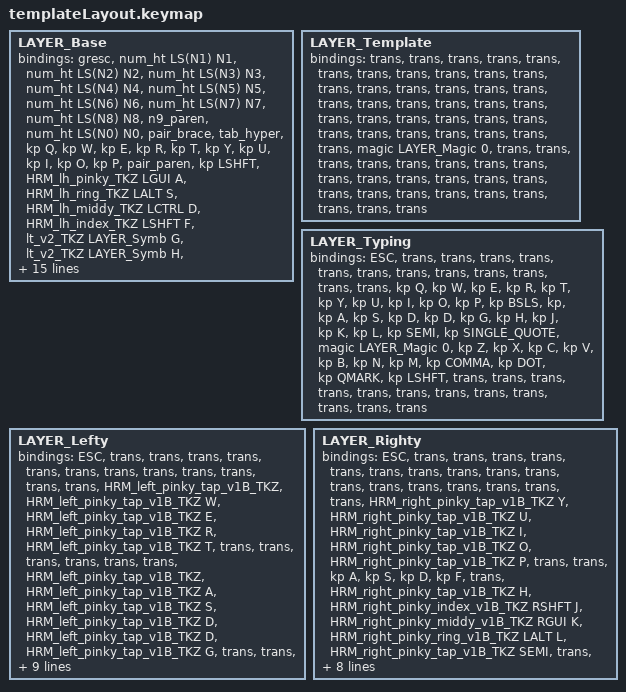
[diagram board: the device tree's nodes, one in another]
/* -------------------------------------------------------------------------- */
/*                    LAYER 0: Base - QWERTY with Home Row Mods               */
/* -------------------------------------------------------------------------- */
#include <behaviors.dtsi>
#include <dt-bindings/zmk/keys.h>
        LAYER_Base {
            bindings = <
/* ╭─────────────────────────────────────╮ ├─────────────────────────────────────┤ ├─────────────────────────────────────┤ ├─────────────────────────────────────┤ ├─────────────────────────────────────┤ ├─────────────────────────────────────┤                                      ├─────────────────────────────────────┤ ├─────────────────────────────────────┤ ├─────────────────────────────────────┤ ├─────────────────────────────────────┤ ├─────────────────────────────────────┤ ├─────────────────────────────────────┤ */
/* │                ESC/`                │ │                   1/!               │ │                   2/@               │ │                 3/#                 │ │                  4/$                │ │                  5/%                │                                      │                  6/^                │ │                   7/&               │ │                  8/*                │ │                   9/()              │ │                 0/)                 │ │                   {}                │ */
                 &gresc                             &num_ht LS(N1) N1                        &num_ht LS(N2) N2                      &num_ht LS(N3) N3                       &num_ht LS(N4) N4                         &num_ht LS(N5) N5                                                            &num_ht LS(N6) N6                      &num_ht LS(N7) N7                         &num_ht LS(N8) N8                           &n9_paren                           &num_ht LS(N0) N0                          &pair_brace
/* ├─────────────────────────────────────┤ ├─────────────────────────────────────┤ ├─────────────────────────────────────┤ ├─────────────────────────────────────┤ ├─────────────────────────────────────┤ ├─────────────────────────────────────┤                                      ├─────────────────────────────────────┤ ├─────────────────────────────────────┤ ├─────────────────────────────────────┤ ├─────────────────────────────────────┤ ├─────────────────────────────────────┤ ├─────────────────────────────────────┤ */
/* │                TAB                  │ │                    Q                │ │                   W                 │ │                   E                 │ │                   R                 │ │                   T                 │                                      │                   Y                 │ │                   U                 │ │                  I                  │ │                  O                  │ │                  P                  │ │                   ()                │ */
                &tab_hyper                                    &kp Q                                  &kp W                                   &kp E                                   &kp R                                 &kp T                                                                           &kp Y                                   &kp U                                   &kp I                                   &kp O                                &kp P                                  &pair_paren
/* ├─────────────────────────────────────┤ ├─────────────────────────────────────┤ ├─────────────────────────────────────┤ ├─────────────────────────────────────┤ ├─────────────────────────────────────┤ ├─────────────────────────────────────┤                                      ├─────────────────────────────────────┤ ├─────────────────────────────────────┤ ├─────────────────────────────────────┤ ├─────────────────────────────────────┤ ├─────────────────────────────────────┤ ├─────────────────────────────────────┤ */
/* │         Lshift + 2xCAPSLCK          │ │            GUI(hold)/A              │ │             ALT(hold)/S             │ │             CTRL(hold)/D            │ │            SHIFT(hold)/F            │ │              SYMB(hold)/G           │                                      │             SYMB(hold)/H            │ │             SHIFT(hold)/J           │ │               CTRL(hold)/K          │ │              ALT(hold)/L            │ │            GUI(hold)/;              │ │                   ""                │ */
                &kp LSHFT                           &HRM_lh_pinky_TKZ LGUI A                &HRM_lh_ring_TKZ LALT S               &HRM_lh_middy_TKZ LCTRL D             &HRM_lh_index_TKZ LSHFT F                   &lt_v2_TKZ LAYER_Symb G                                                     &lt_v2_TKZ LAYER_Symb H                 &HRM_rh_index_TKZ RSHFT J               &HRM_rh_middy_TKZ RCTRL K               &HRM_rh_ring_TKZ RALT L              &HRM_rh_pinky_TKZ RGUI SEMI                        &dqt_pair
/* ├─────────────────────────────────────┤ ├─────────────────────────────────────┤ ├─────────────────────────────────────┤ ├─────────────────────────────────────┤ ├─────────────────────────────────────┤ ├─────────────────────────────────────┤                                      ├─────────────────────────────────────┤ ├─────────────────────────────────────┤ ├─────────────────────────────────────┤ ├─────────────────────────────────────┤ ├─────────────────────────────────────┤ ├─────────────────────────────────────┤ */
/* │               MAGIC                 │ │                    Z                │ │                    X                │ │                  C                  │ │                   V                 │ │                 B                   │                                      │                   N                 │ │                   M                 │ │                 ,/<>                │ │                   .                 │ │                  /                  │ │                 NUMPAD              │ */
          &magic LAYER_Magic 0                                &kp Z                                   &kp X                                 &kp C                                    &kp V                                 &kp B                                                                          &kp N                                  &kp M                                &comma_angle                               &kp DOT                               &kp FSLH                                 &numpad_td
/* ╰─────────────────────────────────────╯ ╰─────────────────────────────────────┤ ├─────────────────────────────────────┤ ├─────────────────────────────────────┤ ├─────────────────────────────────────┤ ╰─────────────────────────────────────╯                                      ╰─────────────────────────────────────╯ ├─────────────────────────────────────┤ ├─────────────────────────────────────┤ ├─────────────────────────────────────┤ ├─────────────────────────────────────┼─┼─────────────────────────────────────╯ */
/*                                                                                 │                  LCTRL              │ │                   LALT              │ │                 CMD                 │                                                                                                                      │            LEFT/WORD-LEFT           │ │                 DOWN                │ │            RIGHT/WORD-RIGHT         │ */
                                                                                                    &kp LCTRL                                &kp LALT                              &kp LGUI                                                                                                                                            &arrow_left LC(LEFT) LEFT                   &upDownArrows                     &arrow_right LC(RIGHT) RIGHT
/*                                                                                 ╰─────────────────────────────────────╯ ╰─────────────────────────────────────╯ ╰─────────────────────────────────────╯                                                                                                                      ╰─────────────────────────────────────╯ ╰─────────────────────────────────────╯ ╰─────────────────────────────────────╯ */
/*                                                                                                                         ├─────────────────────────────────────┤ ├─────────────────────────────────────┤ ├─────────────────────────────────────┤                                      ├─────────────────────────────────────┤ ├─────────────────────────────────────┤ ├─────────────────────────────────────┤ */
/*                                                                                                                         │           NAV(hold)/SPACE           │ │                ENTER                │ │             NUMPAD(hold)/?          │                                      │              SYMB(hold)/.           │ │             BSPC/DEL-WORD           │ │          NAV(hold)/SPACE            │ */
                                                                                                                                &space_v3_TKZ LAYER_Nav SPACE               &lt_v2_TKZ LAYER_Num RET             &lt_v2_TKZ LAYER_Symb QMARK                                                &lt_v2_TKZ LAYER_Symb PERIOD                &bspc_word LA(BSPC) BSPC            &space_v3_TKZ LAYER_Nav SPACE
/*                                                                                                                         ╰─────────────────────────────────────╯ ╰─────────────────────────────────────╯ ╰─────────────────────────────────────╯                                      ╰─────────────────────────────────────╯ ╰─────────────────────────────────────╯ ╰─────────────────────────────────────╯ */
            >;
        };

/* -------------------------------------------------------------------------- */
/*                    LAYER 1: Template                                                */ 
/* -------------------------------------------------------------------------- */
        LAYER_Template {
            bindings = <
/* ╭─────────────────────────────────────╮ ├─────────────────────────────────────┤ ├─────────────────────────────────────┤ ├─────────────────────────────────────┤ ├─────────────────────────────────────┤ ├─────────────────────────────────────┤                                      ├─────────────────────────────────────┤ ├─────────────────────────────────────┤ ├─────────────────────────────────────┤ ├─────────────────────────────────────┤ ├─────────────────────────────────────┤ ├─────────────────────────────────────┤ */
/* │                ---                  │ │                   ---               │ │                  ---                │ │                 ---                 │ │                  ---                │ │                  ---                │                                      │                 ---                 │ │                  ---                │ │                 ---                 │ │                 ---                 │ │                ---                  │ │                  ---                │ */
                 &trans                                     &trans                                  &trans                                  &trans                                  &trans                                 &trans                                                                       &trans                                    &trans                                &trans                                    &trans                                 &trans                                     &trans
/* ├─────────────────────────────────────┤ ├─────────────────────────────────────┤ ├─────────────────────────────────────┤ ├─────────────────────────────────────┤ ├─────────────────────────────────────┤ ├─────────────────────────────────────┤                                      ├─────────────────────────────────────┤ ├─────────────────────────────────────┤ ├─────────────────────────────────────┤ ├─────────────────────────────────────┤ ├─────────────────────────────────────┤ ├─────────────────────────────────────┤ */
/* │                ---                  │ │                   ---               │ │                  ---                │ │                 ---                 │ │                  ---                │ │                 ---                 │                                      │                 ---                 │ │                  ---                │ │                 ---                 │ │                  ---                │ │                ---                  │ │                  ---                │ */
                 &trans                                     &trans                                  &trans                                   &trans                                  &trans                                 &trans                                                                        &trans                                  &trans                                &trans                                  &trans                                 &trans                                     &trans
/* ├─────────────────────────────────────┤ ├─────────────────────────────────────┤ ├─────────────────────────────────────┤ ├─────────────────────────────────────┤ ├─────────────────────────────────────┤ ├─────────────────────────────────────┤                                      ├─────────────────────────────────────┤ ├─────────────────────────────────────┤ ├─────────────────────────────────────┤ ├─────────────────────────────────────┤ ├─────────────────────────────────────┤ ├─────────────────────────────────────┤ */
/* │                ---                  │ │            GUI(hold)/A              │ │                  ---                │ │                 ---                 │ │                  ---                │ │                ---                  │                                      │                 ---                 │ │                  ---                │ │                 ---                 │ │                 ---                 │ │                ---                  │ │                   ---               │ */
                 &trans                                     &trans                                  &trans                                  &trans                                  &trans                                 &trans                                                                        &trans                                   &trans                                &trans                                   &trans                                 &trans                                     &trans
/* ├─────────────────────────────────────┤ ├─────────────────────────────────────┤ ├─────────────────────────────────────┤ ├───────────────────── ───────────────┤ ├─────────────────────────────────────┤ ├─────────────────────────────────────┤                                      ├─────────────────────────────────────┤ ├─────────────────────────────────────┤ ├─────────────────────────────────────┤ ├─────────────────────────────────────┤ ├─────────────────────────────────────┤ ├─────────────────────────────────────┤ */
/* │               MAGIC                 │ │                    Z                │ │                 ---                 │ │                 ---                 │ │                  ---                │ │                 ---                 │                                      │                 ---                 │ │                  ---                │ │                 ---                 │ │                 ---                 │ │                ---                  │ │                   ---               │ */
          &magic LAYER_Magic 0                              &trans                                  &trans                                  &trans                                  &trans                                 &trans                                                                        &trans                                   &trans                                &trans                                   &trans                                 &trans                                     &trans
/* ╰─────────────────────────────────────╯ ╰─────────────────────────────────────┤ ├─────────────────────────────────────┤ ├─────────────────────────────────────┤ ├─────────────────────────────────────┤ ╰─────────────────────────────────────╯                                      ╰─────────────────────────────────────╯ ├─────────────────────────────────────┤ ├─────────────────────────────────────┤ ├─────────────────────────────────────┤ ├─────────────────────────────────────┼─┼─────────────────────────────────────╯ */
/*                                                                                 │                  LCTRL              │ │                   ---               │ │                  ---                 │                                                                                                                      │                 ---                 │ │                ---                  │ │                   ---               │ */
                                                                                                    &trans                                  &trans                                  &trans                                                                                                                                                        &trans                                &trans                                    &trans
/*                                                                                 ╰─────────────────────────────────────╯ ╰─────────────────────────────────────╯ ╰─────────────────────────────────────╯                                                                                                                      ╰─────────────────────────────────────╯ ╰─────────────────────────────────────╯ ╰─────────────────────────────────────╯ */
/*                                                                                                                         ├─────────────────────────────────────┤ ├─────────────────────────────────────┤ ├─────────────────────────────────────┤                                      ├─────────────────────────────────────┤ ├─────────────────────────────────────┤ ├─────────────────────────────────────┤ */
/*                                                                                                                         │                ---                  │ │                   ---               │ │                ---                  │                                      │                 ---                 │ │                  ---                │ │                 ---                 │ */
                                                                                                                                            &trans                                  &trans                                 &trans                                                                       &trans                                    &trans                                &trans 
/*                                                                                                                         ╰─────────────────────────────────────╯ ╰─────────────────────────────────────╯ ╰─────────────────────────────────────╯                                      ╰─────────────────────────────────────╯ ╰─────────────────────────────────────╯ ╰─────────────────────────────────────╯ */
            >;
        };

/* -------------------------------------------------------------------------- */
/*                    LAYER 1: Typing                                                */ 
/* -------------------------------------------------------------------------- */
        LAYER_Typing {
            bindings = <
/* ╭─────────────────────────────────────╮ ├─────────────────────────────────────┤ ├─────────────────────────────────────┤ ├─────────────────────────────────────┤ ├─────────────────────────────────────┤ ├─────────────────────────────────────┤                                      ├─────────────────────────────────────┤ ├─────────────────────────────────────┤ ├─────────────────────────────────────┤ ├─────────────────────────────────────┤ ├─────────────────────────────────────┤ ├─────────────────────────────────────┤ */
/* │                Esc                  │ │                   1                 │ │                  2                  │ │                 3                   │ │                  4                  │ │                 5                   │                                      │                  6                  │ │                  7                  │ │                  8                  │ │                  9                  │ │                  0                  │ │                  {}                 │ */
                   &ESC                                    &trans                                  &trans                                 &trans                                    &trans                                 &trans                                                                       &trans                                   &trans                                &trans                                    &trans                                 &trans                                   &trans
/* ├─────────────────────────────────────┤ ├─────────────────────────────────────┤ ├─────────────────────────────────────┤ ├─────────────────────────────────────┤ ├─────────────────────────────────────┤ ├─────────────────────────────────────┤                                      ├─────────────────────────────────────┤ ├─────────────────────────────────────┤ ├─────────────────────────────────────┤ ├─────────────────────────────────────┤ ├─────────────────────────────────────┤ ├─────────────────────────────────────┤ */
/* │                Tab                  │ │                   Q                 │ │                  W                  │ │                 E                   │ │                  R                  │ │                 T                   │                                      │                  Y                  │ │                  U                  │ │                  I                  │ │                  O                  │ │                  P                  │ │                  \|                 │ */
                  &trans                                   &kp Q                                   &kp W                                  &kp E                                     &kp R                                  &kp T                                                                        &kp Y                                    &kp U                                  &kp I                                  &kp O                                    &kp P                                   &kp BSLS
/* ├─────────────────────────────────────┤ ├─────────────────────────────────────┤ ├─────────────────────────────────────┤ ├─────────────────────────────────────┤ ├─────────────────────────────────────┤ ├─────────────────────────────────────┤                                      ├─────────────────────────────────────┤ ├─────────────────────────────────────┤ ├─────────────────────────────────────┤ ├─────────────────────────────────────┤ ├─────────────────────────────────────┤ ├─────────────────────────────────────┤ */
/* │               CAPS                  │ │                   A                 │ │                  S                  │ │                 D                   │ │                  F                  │ │                 G                   │                                      │                 H                   │ │                  J                  │ │                  K                  │ │                 L                   │ │                SEMI                 │ │                  QUOTE              │ */
                   &kp                                     &kp A                                   &kp S                                  &kp D                                     &kp D                                  &kp G                                                                        &kp H                                    &kp J                                  &kp K                                  &kp L                                   &kp SEMI                               &kp SINGLE_QUOTE
/* ├─────────────────────────────────────┤ ├─────────────────────────────────────┤ ├─────────────────────────────────────┤ ├───────────────────── ───────────────┤ ├─────────────────────────────────────┤ ├─────────────────────────────────────┤                                      ├─────────────────────────────────────┤ ├─────────────────────────────────────┤ ├─────────────────────────────────────┤ ├─────────────────────────────────────┤ ├─────────────────────────────────────┤ ├─────────────────────────────────────┤ */
/* │               MAGIC                 │ │                   Z                 │ │                 X                   │ │                 C                   │ │                  V                  │ │                 B                   │                                      │                 N                   │ │                  M                  │ │               COMMA                 │ │                DOT                  │ │               QMARK                 │ │                 LSHFT               │ */
          &magic LAYER_Magic 0                             &kp Z                                   &kp X                                  &kp C                                     &kp V                                  &kp B                                                                        &kp N                                    &kp M                                &kp COMMA                                &kp DOT                                &kp QMARK                                  &kp LSHFT
/* ╰─────────────────────────────────────╯ ╰─────────────────────────────────────┤ ├─────────────────────────────────────┤ ├─────────────────────────────────────┤ ├─────────────────────────────────────┤ ╰─────────────────────────────────────╯                                      ╰─────────────────────────────────────╯ ├─────────────────────────────────────┤ ├─────────────────────────────────────┤ ├─────────────────────────────────────┤ ├─────────────────────────────────────┼─┼─────────────────────────────────────╯ */
/*                                                                                 │                  LCTRL              │ │                 ---                 │ │                ---                  │                                                                                                                      │                ---                  │ │                ---                  │ │                  ---                │ */
                                                                                                     &trans                                  &trans                                 &trans                                                                                                                                                      &trans                                  &trans                                     &trans
/*                                                                                 ╰─────────────────────────────────────╯ ╰─────────────────────────────────────╯ ╰─────────────────────────────────────╯                                                                                                                     ╰─────────────────────────────────────╯ ╰─────────────────────────────────────╯ ╰─────────────────────────────────────╯ */
/*                                                                                                                         ├─────────────────────────────────────┤ ├─────────────────────────────────────┤ ├─────────────────────────────────────┤                                      ├─────────────────────────────────────┤ ├─────────────────────────────────────┤ ├─────────────────────────────────────┤ */
/*                                                                                                                         │                ---                  │ │                   ---               │ │                ---                  │                                      │                 ---                 │ │                  ---                │ │                 ---                 │ */
                                                                                                                                          &trans                                    &trans                                 &trans                                                                       &trans                                    &trans                                &trans 
/*                                                                                                                         ╰─────────────────────────────────────╯ ╰─────────────────────────────────────╯ ╰─────────────────────────────────────╯                                      ╰─────────────────────────────────────╯ ╰─────────────────────────────────────╯ ╰─────────────────────────────────────╯ */
            >;
        };

    LAYER_Lefty {
            bindings = <
/* ╭─────────────────────────────────────╮ ├─────────────────────────────────────┤ ├─────────────────────────────────────┤ ├─────────────────────────────────────┤ ├─────────────────────────────────────┤ ├─────────────────────────────────────┤                                      ├─────────────────────────────────────┤ ├─────────────────────────────────────┤ ├─────────────────────────────────────┤ ├─────────────────────────────────────┤ ├─────────────────────────────────────┤ ├─────────────────────────────────────┤ */
/* │                Esc                  │ │                   1                 │ │                  2                  │ │                 3                   │ │                  4                  │ │                 5                   │                                      │                  6                  │ │                  7                  │ │                  8                  │ │                  9                  │ │                  0                  │ │                  {}                 │ */
                   &ESC                                    &trans                                  &trans                                 &trans                                    &trans                                 &trans                                                                       &trans                                   &trans                                 &trans                                  &trans                                  &trans                                   &trans
/* ├─────────────────────────────────────┤ ├─────────────────────────────────────┤ ├─────────────────────────────────────┤ ├─────────────────────────────────────┤ ├─────────────────────────────────────┤ ├─────────────────────────────────────┤                                      ├─────────────────────────────────────┤ ├─────────────────────────────────────┤ ├─────────────────────────────────────┤ ├─────────────────────────────────────┤ ├─────────────────────────────────────┤ ├─────────────────────────────────────┤ */
/* │                ---                  │ │                   Q                 │ │                  W                  │ │                 E                   │ │                  R                  │ │                 T                   │                                      │                  Y                  │ │                  U                  │ │                  I                  │ │                  O                  │ │                  P                  │ │                  \|                 │ */
                  &trans                        &HRM_left_pinky_tap_v1B_TKZ              &HRM_left_pinky_tap_v1B_TKZ W            &HRM_left_pinky_tap_v1B_TKZ E          &HRM_left_pinky_tap_v1B_TKZ R           &HRM_left_pinky_tap_v1B_TKZ T                                                           &trans                                   &trans                                 &trans                                  &trans                                  &trans                                   &trans
/* ├─────────────────────────────────────┤ ├─────────────────────────────────────┤ ├─────────────────────────────────────┤ ├─────────────────────────────────────┤ ├─────────────────────────────────────┤ ├─────────────────────────────────────┤                                      ├─────────────────────────────────────┤ ├─────────────────────────────────────┤ ├─────────────────────────────────────┤ ├─────────────────────────────────────┤ ├─────────────────────────────────────┤ ├─────────────────────────────────────┤ */
/* │               CAPS                  │ │                   A                 │ │                  S                  │ │                 D                   │ │                  F                  │ │                 G                   │                                      │                 H                   │ │                  J                  │ │                  K                  │ │                 L                   │ │                SEMI                 │ │                  QUOTE              │ */
        &HRM_left_pinky_tap_v1B_TKZ             &HRM_left_pinky_tap_v1B_TKZ A           &HRM_left_pinky_tap_v1B_TKZ S            &HRM_left_pinky_tap_v1B_TKZ D          &HRM_left_pinky_tap_v1B_TKZ D           &HRM_left_pinky_tap_v1B_TKZ G                                                           &trans                                   &trans                                 &trans                                  &trans                                  &trans                                   &trans
/* ├─────────────────────────────────────┤ ├─────────────────────────────────────┤ ├─────────────────────────────────────┤ ├───────────────────── ───────────────┤ ├─────────────────────────────────────┤ ├─────────────────────────────────────┤                                      ├─────────────────────────────────────┤ ├─────────────────────────────────────┤ ├─────────────────────────────────────┤ ├─────────────────────────────────────┤ ├─────────────────────────────────────┤ ├─────────────────────────────────────┤ */
/* │               MAGIC                 │ │                   Z                 │ │                 X                   │ │                 C                   │ │                  V                  │ │                 B                   │                                      │                 N                   │ │                  M                  │ │               COMMA                 │ │                DOT                  │ │               QMARK                 │ │                 LSHFT               │ */
                  &trans                        &HRM_left_pinky_tap_v1B_TKZ Z           &HRM_left_pinky_tap_v1B_TKZ X            &HRM_left_pinky_tap_v1B_TKZ C          &HRM_left_pinky_tap_v1B_TKZ V           &HRM_left_pinky_tap_v1B_TKZ B                                                           &trans                                  &trans                                  &trans                                  &trans                                  &trans                                   &trans
/* ╰─────────────────────────────────────╯ ╰─────────────────────────────────────┤ ├─────────────────────────────────────┤ ├─────────────────────────────────────┤ ├─────────────────────────────────────┤ ╰─────────────────────────────────────╯                                      ╰─────────────────────────────────────╯ ├─────────────────────────────────────┤ ├─────────────────────────────────────┤ ├─────────────────────────────────────┤ ├─────────────────────────────────────┼─┼─────────────────────────────────────╯ */
/*                                                                                 │                  LCTRL              │ │                 ---                 │ │                ---                  │                                                                                                                      │                ---                  │ │                ---                  │ │                  ---                │ */
                                                                                                    &trans                                  &trans                                 &trans                                                                                                                                                       &trans                                  &trans                                     &trans
/*                                                                                 ╰─────────────────────────────────────╯ ╰─────────────────────────────────────╯ ╰─────────────────────────────────────╯                                                                                                                      ╰─────────────────────────────────────╯ ╰─────────────────────────────────────╯ ╰─────────────────────────────────────╯ */
/*                                                                                                                         ├─────────────────────────────────────┤ ├─────────────────────────────────────┤ ├─────────────────────────────────────┤                                      ├─────────────────────────────────────┤ ├─────────────────────────────────────┤ ├─────────────────────────────────────┤ */
/*                                                                                                                         │                ---                  │ │                   ---               │ │                ---                  │                                      │                 ---                 │ │                  ---                │ │                 ---                 │ */
                                                                                                                                          &trans                                    &trans                                 &trans                                                                       &trans                                    &trans                                &trans 
/*                                                                                                                         ╰─────────────────────────────────────╯ ╰─────────────────────────────────────╯ ╰─────────────────────────────────────╯                                      ╰─────────────────────────────────────╯ ╰─────────────────────────────────────╯ ╰─────────────────────────────────────╯ */
            >;
        };
    LAYER_Righty {
            bindings = <
/* ╭─────────────────────────────────────╮ ├─────────────────────────────────────┤ ├─────────────────────────────────────┤ ├─────────────────────────────────────┤ ├─────────────────────────────────────┤ ├─────────────────────────────────────┤                                      ├─────────────────────────────────────┤ ├─────────────────────────────────────┤ ├─────────────────────────────────────┤ ├─────────────────────────────────────┤ ├─────────────────────────────────────┤ ├─────────────────────────────────────┤ */
/* │                Esc                  │ │                   1                 │ │                  2                  │ │                 3                   │ │                  4                  │ │                 5                   │                                      │                  6                  │ │                  7                  │ │                  8                  │ │                  9                  │ │                  0                  │ │                  {}                 │ */
                   &ESC                                      &trans                                &trans                                  &trans                                   &trans                                 &trans                                                                        &trans                                  &trans                                  &trans                                  &trans                                 &trans                                   &trans
/* ├─────────────────────────────────────┤ ├─────────────────────────────────────┤ ├─────────────────────────────────────┤ ├─────────────────────────────────────┤ ├─────────────────────────────────────┤ ├─────────────────────────────────────┤                                      ├─────────────────────────────────────┤ ├─────────────────────────────────────┤ ├─────────────────────────────────────┤ ├─────────────────────────────────────┤ ├─────────────────────────────────────┤ ├─────────────────────────────────────┤ */
/* │                ---                  │ │                   Q                 │ │                  W                  │ │                 E                   │ │                  R                  │ │                 T                   │                                      │                  Y                  │ │                  U                  │ │                  I                  │ │                  O                  │ │                  P                  │ │                  \|                 │ */
                  &trans                                     &trans                                &trans                                  &trans                                   &trans                                 &trans                                                            &HRM_right_pinky_tap_v1B_TKZ Y          &HRM_right_pinky_tap_v1B_TKZ U         &HRM_right_pinky_tap_v1B_TKZ I           &HRM_right_pinky_tap_v1B_TKZ O         &HRM_right_pinky_tap_v1B_TKZ P                       &trans
/* ├─────────────────────────────────────┤ ├─────────────────────────────────────┤ ├─────────────────────────────────────┤ ├─────────────────────────────────────┤ ├─────────────────────────────────────┤ ├─────────────────────────────────────┤                                      ├─────────────────────────────────────┤ ├─────────────────────────────────────┤ ├─────────────────────────────────────┤ ├─────────────────────────────────────┤ ├─────────────────────────────────────┤ ├─────────────────────────────────────┤ */
/* │               CAPS                  │ │                   A                 │ │                  S                  │ │                 D                   │ │                  F                  │ │                 G                   │                                      │                 H                   │ │                  J                  │ │                  K                  │ │                 L                   │ │                SEMI                 │ │                  QUOTE              │ */
                  &trans                                     &kp A                                 &kp S                                  &kp D                                     &kp F                                  &trans                                                            &HRM_right_pinky_tap_v1B_TKZ H     &HRM_right_pinky_index_v1B_TKZ RSHFT J   &HRM_right_pinky_middy_v1B_TKZ RGUI K    &HRM_right_pinky_ring_v1B_TKZ LALT L     &HRM_right_pinky_tap_v1B_TKZ SEMI                     &trans
/* ├─────────────────────────────────────┤ ├─────────────────────────────────────┤ ├─────────────────────────────────────┤ ├───────────────────── ───────────────┤ ├─────────────────────────────────────┤ ├─────────────────────────────────────┤                                      ├─────────────────────────────────────┤ ├─────────────────────────────────────┤ ├─────────────────────────────────────┤ ├─────────────────────────────────────┤ ├─────────────────────────────────────┤ ├─────────────────────────────────────┤ */
/* │               MAGIC                 │ │                   Z                 │ │                 X                   │ │                 C                   │ │                  V                  │ │                 B                   │                                      │                 N                   │ │                  M                  │ │               COMMA                 │ │                DOT                  │ │               QMARK                 │ │                 LSHFT               │ */
                  &trans                                     &trans                                &trans                                 &trans                                    &trans                                 &trans                                                            &HRM_right_pinky_tap_v1B_TKZ N          &HRM_right_pinky_tap_v1B_TKZ M       &HRM_right_pinky_tap_v1B_TKZ COMMA       &HRM_right_pinky_tap_v1B_TKZ DOT       &HRM_right_pinky_tap_v1B_TKZ QMARK                     &trans
/* ╰─────────────────────────────────────╯ ╰─────────────────────────────────────┤ ├─────────────────────────────────────┤ ├─────────────────────────────────────┤ ├─────────────────────────────────────┤ ╰─────────────────────────────────────╯                                      ╰─────────────────────────────────────╯ ├─────────────────────────────────────┤ ├─────────────────────────────────────┤ ├─────────────────────────────────────┤ ├─────────────────────────────────────┼─┼─────────────────────────────────────╯ */
/*                                                                                 │                  LCTRL              │ │                 ---                 │ │                ---                  │                                                                                                                      │                ---                  │ │                ---                  │ │                  ---                │ */
                                                                                                      &trans                                &trans                                 &trans                                                                                                                                                        &trans                                  &trans                                    &trans
/*                                                                                 ╰─────────────────────────────────────╯ ╰─────────────────────────────────────╯ ╰─────────────────────────────────────╯                                                                                                                      ╰─────────────────────────────────────╯ ╰─────────────────────────────────────╯ ╰─────────────────────────────────────╯ */
/*                                                                                                                         ├─────────────────────────────────────┤ ├─────────────────────────────────────┤ ├─────────────────────────────────────┤                                      ├─────────────────────────────────────┤ ├─────────────────────────────────────┤ ├─────────────────────────────────────┤ */
/*                                                                                                                         │                ---                  │ │                   ---               │ │                ---                  │                                      │                 ---                 │ │                  ---                │ │                 ---                 │ */
                                                                                                                                          &trans                                    &trans                                 &trans                                                                       &trans                                    &trans                                &trans 
/*                                                                                                                         ╰─────────────────────────────────────╯ ╰─────────────────────────────────────╯ ╰─────────────────────────────────────╯                                      ╰─────────────────────────────────────╯ ╰─────────────────────────────────────╯ ╰─────────────────────────────────────╯ */
            >;
        };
